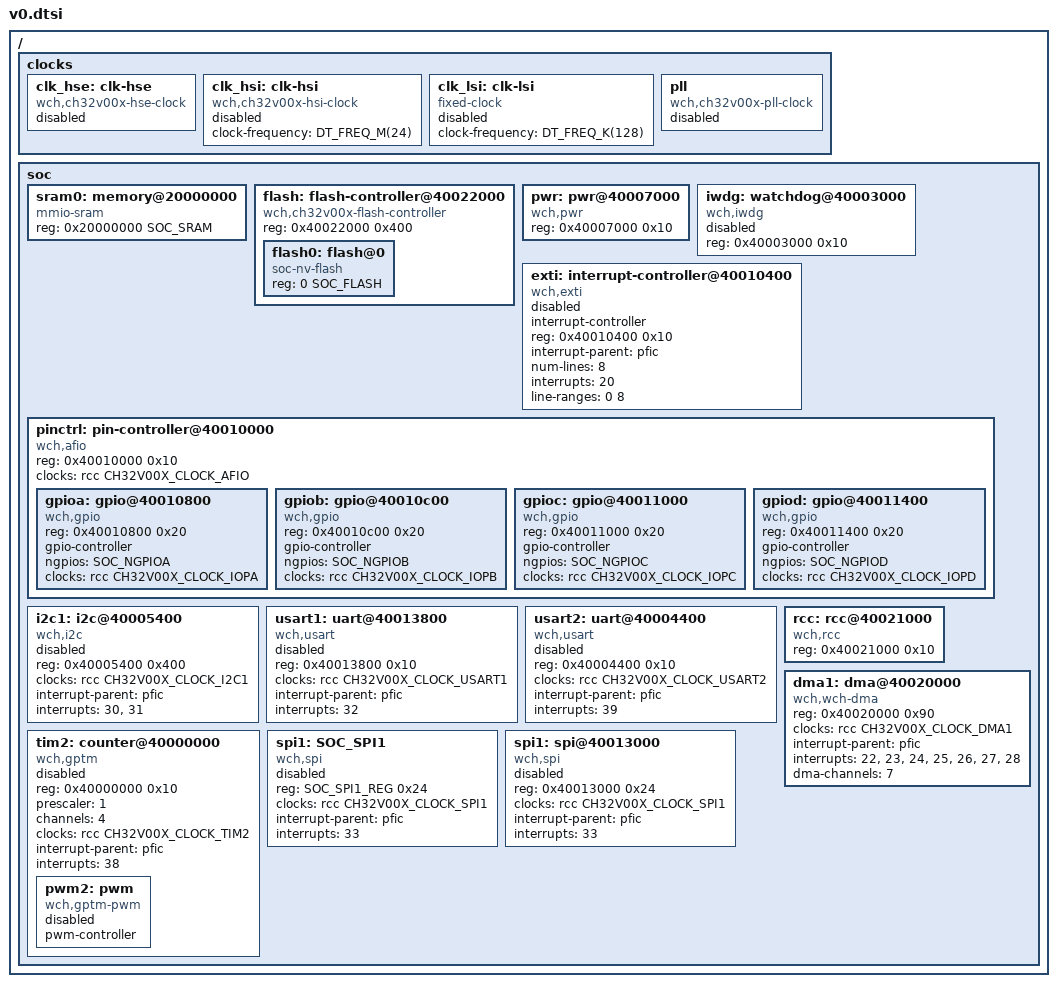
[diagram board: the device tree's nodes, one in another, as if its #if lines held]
/*
 * Copyright (c) 2026 Mike Kasprzak (distraction.engineer)
 *
 * SPDX-License-Identifier: Apache-2.0
 *
 * References: https://www.wch-ic.com/products/QingKe.html?categoryId=77
 *             https://www.wch-ic.com/downloads/QingKeV4_Processor_Manual_PDF.html
 */


#include <freq.h>
#include <mem.h>
#include <zephyr/dt-bindings/gpio/gpio.h>
#include <zephyr/dt-bindings/i2c/i2c.h>
#include <zephyr/dt-bindings/clock/ch32v00x-clocks.h>
#include <zephyr/dt-bindings/dma/ch32v003-dma.h>

//#include "skeleton.dtsi"
//#include <wch/qingke/common/soc.dtsi>

/ {
	clocks {
		clk_hse: clk-hse {
			#clock-cells = <0>;
			compatible = "wch,ch32v00x-hse-clock";
			status = "disabled";
		};

		clk_hsi: clk-hsi {
			#clock-cells = <0>;
			compatible = "wch,ch32v00x-hsi-clock";
			clock-frequency = <DT_FREQ_M(24)>;
			status = "disabled";
		};

		clk_lsi: clk-lsi {
			#clock-cells = <0>;
			compatible = "fixed-clock";
			clock-frequency = <DT_FREQ_K(128)>;
			status = "disabled";
		};

		pll: pll {
			#clock-cells = <0>;
			compatible = "wch,ch32v00x-pll-clock";
			status = "disabled";
		};
	};

	soc {
#ifdef SOC_SRAM
		sram0: memory@20000000 {
			compatible = "mmio-sram";
			reg = <0x20000000 SOC_SRAM>;
		};
#endif /* SOC_SRAM */
#ifdef SOC_FLASH
		flash: flash-controller@40022000 {
			compatible = "wch,ch32v00x-flash-controller";
			reg = <0x40022000 0x400>;

			#address-cells = <1>;
			#size-cells = <1>;

			flash0: flash@0 {
				compatible = "soc-nv-flash";
				reg = <0 SOC_FLASH>;
			};
		};
#endif /* SOC_FLASH */
		pwr: pwr@40007000 {
			compatible = "wch,pwr";
			reg = <0x40007000 0x10>;
		};
#ifdef SOC_WATCHDOG
		iwdg: watchdog@40003000 {
			compatible = "wch,iwdg";
			reg = <0x40003000 0x10>;
			status = "disabled";
		};
#endif /* SOC_WATCHDOG */
		exti: interrupt-controller@40010400 {
			compatible = "wch,exti";
			interrupt-controller;
			#interrupt-cells = <1>;
			reg = <0x40010400 0x10>;
			interrupt-parent = <&pfic>;
			num-lines = <8>;
			interrupts = <20>;
			line-ranges = <0 8>;
			interrupt-names = "line0-7";
			status = "disabled";
		};

		pinctrl: pin-controller@40010000 {
			compatible = "wch,afio";
			reg = <0x40010000 0x10>;
			#address-cells = <1>;
			#size-cells = <1>;
			clocks = <&rcc CH32V00X_CLOCK_AFIO>;
			status = "okay";

#ifdef SOC_NGPIOA
			gpioa: gpio@40010800 {
				compatible = "wch,gpio";
				reg = <0x40010800 0x20>;
				gpio-controller;
				#gpio-cells = <2>;
				ngpios = <SOC_NGPIOA>;
				clocks = <&rcc CH32V00X_CLOCK_IOPA>;
			};
#endif /* SOC_NGPIOA */
#ifdef SOC_NGPIOB
			gpiob: gpio@40010c00 {
				compatible = "wch,gpio";
				reg = <0x40010c00 0x20>;
				gpio-controller;
				#gpio-cells = <2>;
				ngpios = <SOC_NGPIOB>;
				clocks = <&rcc CH32V00X_CLOCK_IOPB>;
			};
#endif /* SOC_NGPIOB */
#ifdef SOC_NGPIOC
			gpioc: gpio@40011000 {
				compatible = "wch,gpio";
				reg = <0x40011000 0x20>;
				gpio-controller;
				#gpio-cells = <2>;
				ngpios = <SOC_NGPIOC>;
				clocks = <&rcc CH32V00X_CLOCK_IOPC>;
			};
#endif /* SOC_NGPIOC */
#ifdef SOC_NGPIOD
			gpiod: gpio@40011400 {
				compatible = "wch,gpio";
				reg = <0x40011400 0x20>;
				gpio-controller;
				#gpio-cells = <2>;
				ngpios = <SOC_NGPIOD>;
				clocks = <&rcc CH32V00X_CLOCK_IOPD>;
			};
#endif /* SOC_NGPIOD */
		};

		i2c1: i2c@40005400 {
			compatible = "wch,i2c";
			#address-cells = <1>;
			#size-cells = <0>;
			reg = <0x40005400 0x400>;
			clocks = <&rcc CH32V00X_CLOCK_I2C1>;
			interrupt-parent = <&pfic>;
			interrupts = <30>, <31>;
			status = "disabled";
		};

		usart1: uart@40013800 {
			compatible = "wch,usart";
			reg = <0x40013800 0x10>;
			clocks = <&rcc CH32V00X_CLOCK_USART1>;
			interrupt-parent = <&pfic>;
			interrupts = <32>;
			status = "disabled";
		};

		usart2: uart@40004400 {
			compatible = "wch,usart";
			reg = <0x40004400 0x10>;
			clocks = <&rcc CH32V00X_CLOCK_USART2>;
			interrupt-parent = <&pfic>;
			interrupts = <39>;
			status = "disabled";
		};

		rcc: rcc@40021000 {
			compatible = "wch,rcc";
			reg = <0x40021000 0x10>;
			#clock-cells = <1>;
			status = "okay";
		};

		dma1: dma@40020000 {
			compatible = "wch,wch-dma";
			reg = <0x40020000 0x90>;
			clocks = <&rcc CH32V00X_CLOCK_DMA1>;
			#dma-cells = <1>;
			interrupt-parent = <&pfic>;
			interrupts = <22>, <23>, <24>, <25>, <26>, <27>, <28>;
			dma-channels = <7>;
		};

		tim2: counter@40000000 {
			compatible = "wch,gptm";
			reg = <0x40000000 0x10>;
			prescaler = <1>;
			channels = <4>;
			clocks = <&rcc CH32V00X_CLOCK_TIM2>;
			interrupt-parent = <&pfic>;
			interrupts = <38>;
			interrupt-names = "global";
			status = "disabled";

			pwm2: pwm {
				compatible = "wch,gptm-pwm";
				pwm-controller;
				#pwm-cells = <3>;
				status = "disabled";
			};
		};

#ifdef SOC_SPI1
		spi1: SOC_SPI1 {
			compatible = "wch,spi";
			reg = <SOC_SPI1_REG 0x24>;
			clocks = <&rcc CH32V00X_CLOCK_SPI1>;
			interrupt-parent = <&pfic>;
			interrupts = <33>;
			status = "disabled";
			#address-cells = <1>;
			#size-cells = <0>;
		};
#endif /* SOC_SPI1 */
#ifdef SOC_SPI2
		spi1: spi@40013000 {
			compatible = "wch,spi";
			reg = <0x40013000 0x24>;
			clocks = <&rcc CH32V00X_CLOCK_SPI1>;
			interrupt-parent = <&pfic>;
			interrupts = <33>;
			status = "disabled";
			#address-cells = <1>;
			#size-cells = <0>;
		};
#endif /* SOC_SPI1 */
	};
};
